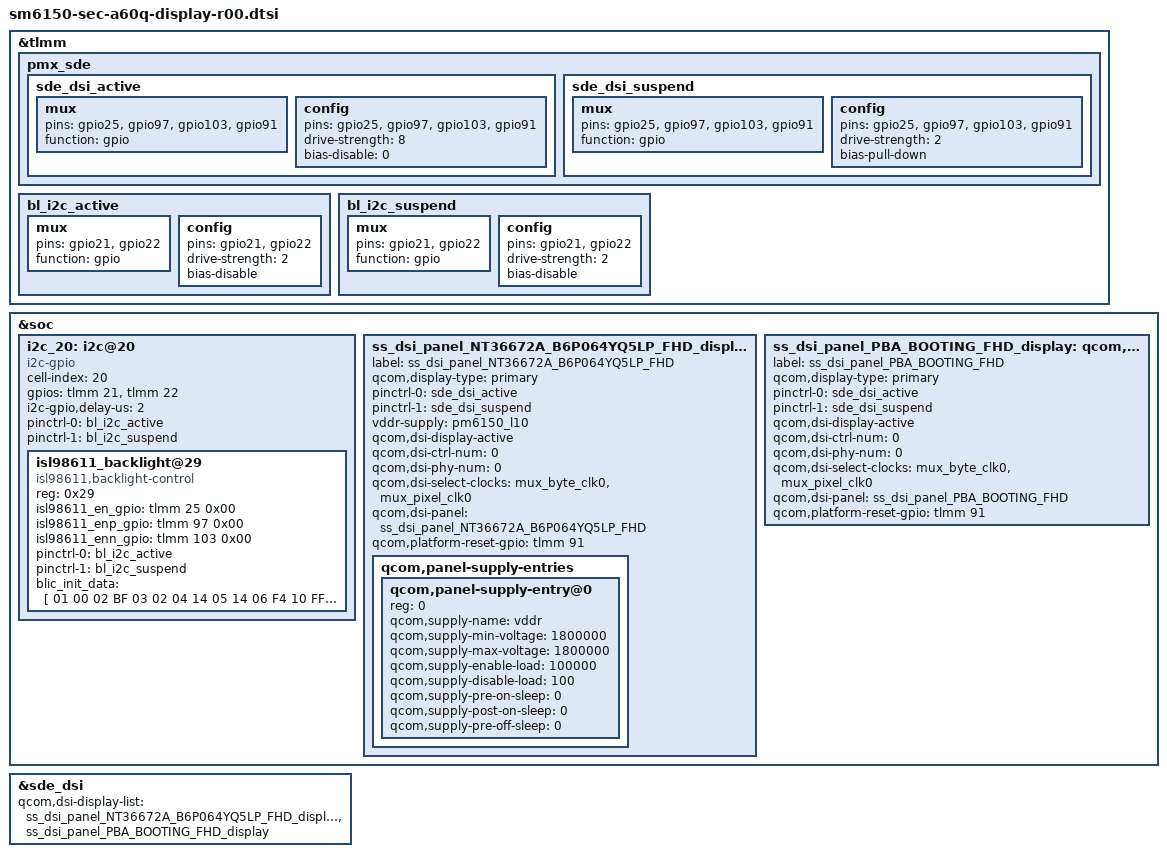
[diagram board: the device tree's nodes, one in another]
/* Copyright (c) 2016-2017, The Linux Foundation. All rights reserved.
 *
 * This program is free software; you can redistribute it and/or modify
 * it under the terms of the GNU General Public License version 2 and
 * only version 2 as published by the Free Software Foundation.
 *
 * This program is distributed in the hope that it will be useful,
 * but WITHOUT ANY WARRANTY; without even the implied warranty of
 * MERCHANTABILITY or FITNESS FOR A PARTICULAR PURPOSE.  See the
 * GNU General Public License for more details.
 */

#include "../../../../../drivers/gpu/drm/msm/samsung/NT36672A_B6P064YQ5LP/dsi_panel_NT36672A_B6P064YQ5LP_fhd_video.dtsi"
#include "../../../../../drivers/gpu/drm/msm/samsung/PBA_BOOTING/dsi_panel_PBA_BOOTING_fhd_video.dtsi"

&tlmm {
	pmx_sde: pmx_sde {
		sde_dsi_active: sde_dsi_active {
			mux {
				pins = "gpio25", "gpio97", "gpio103", "gpio91";/*reset*/
				function = "gpio";
			};

			config {
				pins = "gpio25", "gpio97", "gpio103", "gpio91";/*reset*/
				drive-strength = <8>;   /* 8 mA */
				bias-disable = <0>;   /* no pull */
			};
		};
		sde_dsi_suspend: sde_dsi_suspend {
			mux {
				pins = "gpio25", "gpio97", "gpio103", "gpio91";/*reset*/
				function = "gpio";
			};

			config {
				pins = "gpio25", "gpio97", "gpio103", "gpio91";/*reset*/
				drive-strength = <2>;   /* 2 mA */
				bias-pull-down;         /* PULL DOWN */
			};
		};
	};
#if 1
	bl_i2c_active: bl_i2c_active {
		mux {
			pins = "gpio21", "gpio22";
			function = "gpio";
		};
		config {
			pins = "gpio21", "gpio22";
			drive-strength = <2>;
			bias-disable;
		};

	};
	bl_i2c_suspend: bl_i2c_suspend {
		mux {
			pins = "gpio21", "gpio22";
			function = "gpio";
		};
		config {
			pins = "gpio21", "gpio22";
			drive-strength = <2>;
			bias-disable;
		};
	};
#endif
};

&soc {
#if 1
/*to do: change hw i2c*/
	i2c_20: i2c@20 {
		status = "okay";

		cell-index = <20>;
		compatible = "i2c-gpio";
		gpios = <&tlmm 21 0 /* sda */
			&tlmm 22 0 /* scl */
			>;
		i2c-gpio,delay-us = <2>;
		#address-cells = <1>;
		#size-cells = <0>;

		pinctrl-names = "default", "sleep";
		pinctrl-0 = <&bl_i2c_active>;
		pinctrl-1 = <&bl_i2c_suspend>;

		isl98611_backlight@29 {
			compatible = "isl98611,backlight-control";
			reg = <0x29>;

			isl98611_en_gpio = <&tlmm 25 0x00>;
			isl98611_enp_gpio = <&tlmm 97 0x00>;
			isl98611_enn_gpio = <&tlmm 103 0x00>;

			pinctrl-names = "i2c_default", "i2c_suspend";
			pinctrl-0 = <&bl_i2c_active>;
			pinctrl-1 = <&bl_i2c_suspend>;

			blic_init_data = [
				01		00
				02		BF
				03		02
				04		14
				05		14
				06		F4
				10		FF
				11		07
				12		BF
				13		80
				14		FD
				16		F5
				17		8D
			];
		};
	};
#else
	qupv3_se4_i2c: i2c@a80000 {
		status = "okay";
		isl98611_backlight@29 {
			compatible = "isl98611,backlight-control";
			reg = <0x29>;

			isl98611_en_gpio = <&tlmm 25 0x00>;
			isl98611_enp_gpio = <&tlmm 97 0x00>;
			isl98611_enn_gpio = <&tlmm 103 0x00>;

			blic_init_data = [
				01		00
				02		BF
				03		02
				04		14
				05		14
				06		F4
				10		FF
				11		07
				12		BF
				13		80
				14		FD
				16		F5
				17		8D
			];
		};
	};
#endif
	/* A60Q panel */
	ss_dsi_panel_NT36672A_B6P064YQ5LP_FHD_display: qcom,dsi-display@5 {
		label = "ss_dsi_panel_NT36672A_B6P064YQ5LP_FHD";
		qcom,display-type = "primary";

		pinctrl-names = "panel_active", "panel_suspend";
		pinctrl-0 = <&sde_dsi_active>;
		pinctrl-1 = <&sde_dsi_suspend>;

		vddr-supply = <&pm6150_l10>;
	};

	/* PBA */
	ss_dsi_panel_PBA_BOOTING_FHD_display: qcom,dsi-display@6 {
		label = "ss_dsi_panel_PBA_BOOTING_FHD";
		qcom,display-type = "primary";

		pinctrl-names = "panel_active", "panel_suspend";
		pinctrl-0 = <&sde_dsi_active>;
		pinctrl-1 = <&sde_dsi_suspend>;
	};
};

&sde_dsi {
	qcom,dsi-display-list =
		<&ss_dsi_panel_NT36672A_B6P064YQ5LP_FHD_display
		&ss_dsi_panel_PBA_BOOTING_FHD_display>;
};

&ss_dsi_panel_NT36672A_B6P064YQ5LP_FHD_display {
	qcom,display-type = "primary";
	qcom,dsi-display-active;

	qcom,dsi-ctrl-num = <0>;
	qcom,dsi-phy-num = <0>;
	qcom,dsi-select-clocks = "mux_byte_clk0", "mux_pixel_clk0";

	qcom,dsi-panel = <&ss_dsi_panel_NT36672A_B6P064YQ5LP_FHD>;
	
	qcom,platform-reset-gpio = <&tlmm 91 0>;

	qcom,panel-supply-entries {
		#address-cells = <1>;
		#size-cells = <0>;

		qcom,panel-supply-entry@0 {
		    reg = <0>;
		    qcom,supply-name = "vddr";
		    qcom,supply-min-voltage = <1800000>;
		    qcom,supply-max-voltage = <1800000>;
		    qcom,supply-enable-load = <100000>;
		    qcom,supply-disable-load = <100>;
		    qcom,supply-pre-on-sleep = <0>; /* unit is ms*/
		    qcom,supply-post-on-sleep = <0>;
   		    qcom,supply-pre-off-sleep = <0>;
		};
	};
};

&ss_dsi_panel_PBA_BOOTING_FHD_display {
	qcom,display-type = "primary";
	qcom,dsi-display-active;

	qcom,dsi-ctrl-num = <0>;
	qcom,dsi-phy-num = <0>;
	qcom,dsi-select-clocks = "mux_byte_clk0", "mux_pixel_clk0";

	qcom,dsi-panel = <&ss_dsi_panel_PBA_BOOTING_FHD>;

	qcom,platform-reset-gpio = <&tlmm 91 0>;
};
